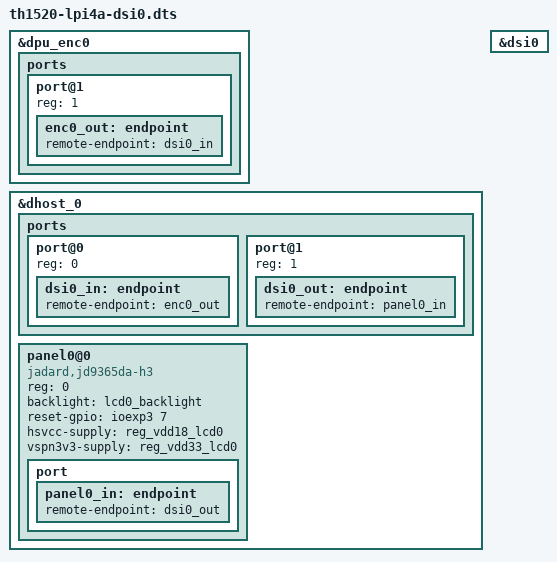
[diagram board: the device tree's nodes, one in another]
// SPDX-License-Identifier: (GPL-2.0 OR MIT)
/*
 * Copyright (C) 2021-2024 Alibaba Group Holding Limited.
 */

#include "th1520-lichee-pi-4a.dts"

&dpu_enc0 {
	status = "okay";

	ports {
		/* output */
		port@1 {
			reg = <1>;

			enc0_out: endpoint {
				remote-endpoint = <&dsi0_in>;
			};
		};
	};
};

&dhost_0 {
	ports {
		#address-cells = <1>;
		#size-cells = <0>;

		port@0 {
			reg = <0>;

			dsi0_in: endpoint {
				remote-endpoint = <&enc0_out>;
			};
		};

		port@1 {
			reg = <1>;

			dsi0_out: endpoint {
				remote-endpoint = <&panel0_in>;
			};
		};
	};

	panel0@0 {
		compatible = "jadard,jd9365da-h3";
		reg = <0>;
		backlight = <&lcd0_backlight>;
		reset-gpio = <&ioexp3 7 0>; /* active low */
		hsvcc-supply = <&reg_vdd18_lcd0>;
		vspn3v3-supply = <&reg_vdd33_lcd0>;

		port {
			panel0_in: endpoint {
				remote-endpoint = <&dsi0_out>;
			};
		};
	};
};

&dsi0 {
	status = "okay";
};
